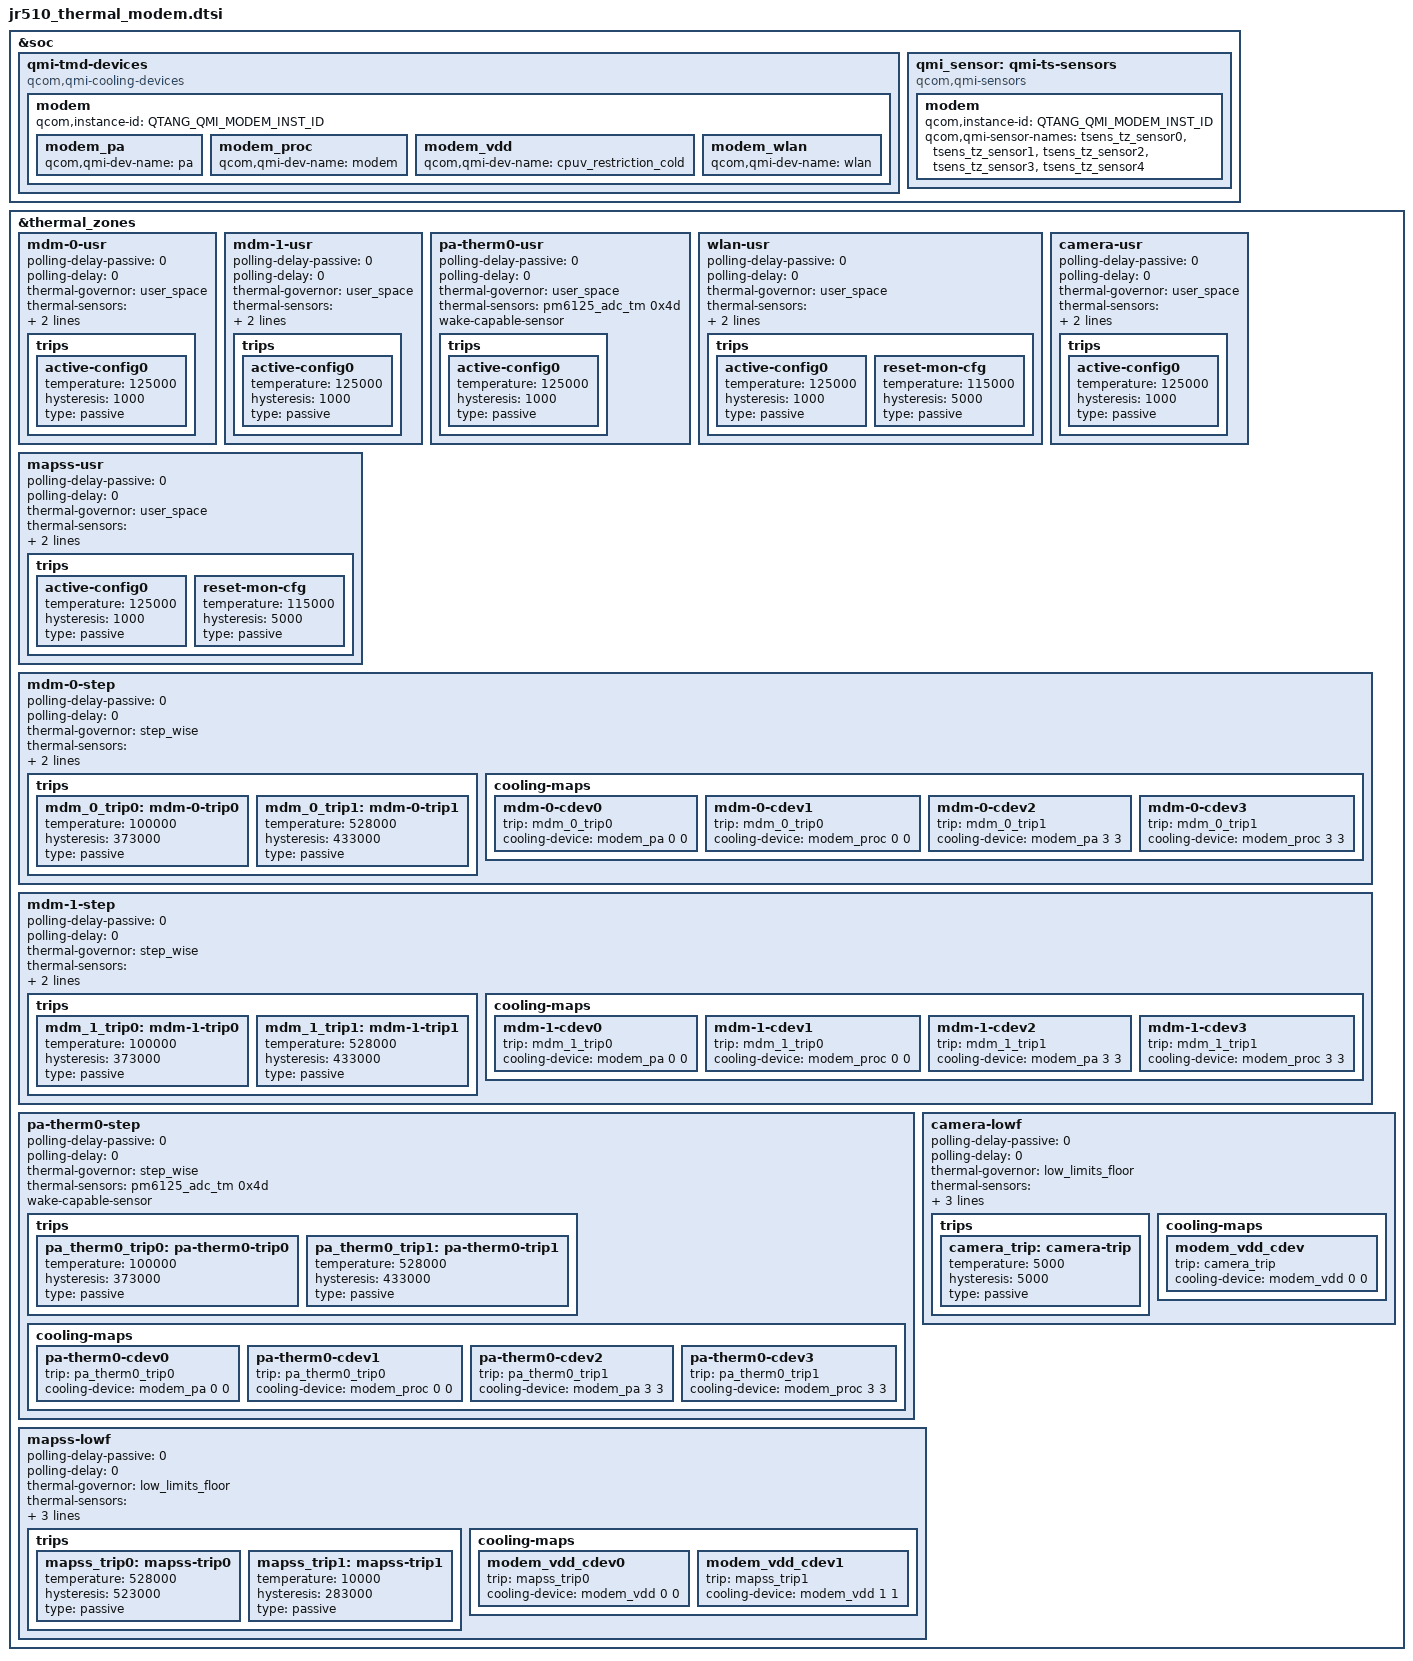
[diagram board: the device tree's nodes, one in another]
// SPDX-License-Identifier: GPL-2.0+

&soc {
	qmi-tmd-devices {
		compatible = "qcom,qmi-cooling-devices";

		modem {
			qcom,instance-id = <QTANG_QMI_MODEM_INST_ID>;

			modem_pa: modem_pa {
				qcom,qmi-dev-name = "pa";
				#cooling-cells = <2>;
			};

			modem_proc: modem_proc {
				qcom,qmi-dev-name = "modem";
				#cooling-cells = <2>;
			};

			modem_vdd: modem_vdd {
				qcom,qmi-dev-name = "cpuv_restriction_cold";
				#cooling-cells = <2>;
			};

			modem_wlan: modem_wlan {
				qcom,qmi-dev-name = "wlan";
				#cooling-cells = <2>;
			};

		};
	};

	qmi_sensor: qmi-ts-sensors {
		compatible = "qcom,qmi-sensors";
		#thermal-sensor-cells = <1>;

		modem {
			qcom,instance-id = <QTANG_QMI_MODEM_INST_ID>;
			qcom,qmi-sensor-names = "tsens_tz_sensor0",
						"tsens_tz_sensor1",
						"tsens_tz_sensor2",
						"tsens_tz_sensor3",
						"tsens_tz_sensor4";
		};
	};
};

&thermal_zones {

	mdm-0-usr {
		polling-delay-passive = <0>;
		polling-delay = <0>;
		thermal-governor = "user_space";
		thermal-sensors = <&qmi_sensor (QTANG_QMI_MODEM_INST_ID
					+QTANG_QMI_MODEM_TSENS_TZ_SENSOR4)>;
		wake-capable-sensor;
		trips {
			active-config0 {
				temperature = <125000>;
				hysteresis = <1000>;
				type = "passive";
			};
		};
	};

	mdm-1-usr {
		polling-delay-passive = <0>;
		polling-delay = <0>;
		thermal-governor = "user_space";
		thermal-sensors = <&qmi_sensor (QTANG_QMI_MODEM_INST_ID
					+QTANG_QMI_MODEM_TSENS_TZ_SENSOR3)>;
		wake-capable-sensor;
		trips {
			active-config0 {
				temperature = <125000>;
				hysteresis = <1000>;
				type = "passive";
			};
		};
	};

	pa-therm0-usr {
		polling-delay-passive = <0>;
		polling-delay = <0>;
		thermal-governor = "user_space";
		thermal-sensors = <&pm6125_adc_tm 0x4d>;
		wake-capable-sensor;
		trips {
			active-config0 {
				temperature = <125000>;
				hysteresis = <1000>;
				type = "passive";
			};
		};
	};

	wlan-usr {
		polling-delay-passive = <0>;
		polling-delay = <0>;
		thermal-governor = "user_space";
		thermal-sensors = <&qmi_sensor (QTANG_QMI_MODEM_INST_ID
					+QTANG_QMI_MODEM_TSENS_TZ_SENSOR1)>;
		wake-capable-sensor;
		trips {
			active-config0 {
				temperature = <125000>;
				hysteresis = <1000>;
				type = "passive";
			};

			reset-mon-cfg {
				temperature = <115000>;
				hysteresis = <5000>;
				type = "passive";
			};
		};
	};

	camera-usr {
		polling-delay-passive = <0>;
		polling-delay = <0>;
		thermal-governor = "user_space";
		thermal-sensors = <&qmi_sensor (QTANG_QMI_MODEM_INST_ID
					+QTANG_QMI_MODEM_TSENS_TZ_SENSOR2)>;
		wake-capable-sensor;
		trips {
			active-config0 {
				temperature = <125000>;
				hysteresis = <1000>;
				type = "passive";
			};
		};
	};

	mapss-usr {
		polling-delay-passive = <0>;
		polling-delay = <0>;
		thermal-governor = "user_space";
		thermal-sensors = <&qmi_sensor (QTANG_QMI_MODEM_INST_ID
					+QTANG_QMI_MODEM_TSENS_TZ_SENSOR0)>;
		wake-capable-sensor;
		trips {
			active-config0 {
				temperature = <125000>;
				hysteresis = <1000>;
				type = "passive";
			};

			reset-mon-cfg {
				temperature = <115000>;
				hysteresis = <5000>;
				type = "passive";
			};
		};
	};

	mdm-0-step {
		polling-delay-passive = <0>;
		polling-delay = <0>;
		thermal-governor = "step_wise";
		thermal-sensors = <&qmi_sensor (QTANG_QMI_MODEM_INST_ID
					+QTANG_QMI_MODEM_TSENS_TZ_SENSOR4)>;
		wake-capable-sensor;

		trips {

			mdm_0_trip0: mdm-0-trip0 {
				temperature = <100000>;
				hysteresis = <373000>;
				type = "passive";
			};

			mdm_0_trip1: mdm-0-trip1 {
				temperature = <528000>;
				hysteresis = <433000>;
				type = "passive";
			};

		};

		cooling-maps {
			mdm-0-cdev0 {
				trip = <&mdm_0_trip0>;
				cooling-device = <&modem_pa 0 0>;
			};
			mdm-0-cdev1 {
				trip = <&mdm_0_trip0>;
				cooling-device = <&modem_proc 0 0>;
			};
			mdm-0-cdev2 {
				trip = <&mdm_0_trip1>;
				cooling-device = <&modem_pa 3 3>;
			};
			mdm-0-cdev3 {
				trip = <&mdm_0_trip1>;
				cooling-device = <&modem_proc 3 3>;
			};
		};

	};

	mdm-1-step {
		polling-delay-passive = <0>;
		polling-delay = <0>;
		thermal-governor = "step_wise";
		thermal-sensors = <&qmi_sensor (QTANG_QMI_MODEM_INST_ID
					+QTANG_QMI_MODEM_TSENS_TZ_SENSOR3)>;
		wake-capable-sensor;

		trips {

			mdm_1_trip0: mdm-1-trip0 {
				temperature = <100000>;
				hysteresis = <373000>;
				type = "passive";
			};

			mdm_1_trip1: mdm-1-trip1 {
				temperature = <528000>;
				hysteresis = <433000>;
				type = "passive";
			};

		};

		cooling-maps {
			mdm-1-cdev0 {
				trip = <&mdm_1_trip0>;
				cooling-device = <&modem_pa 0 0>;
			};
			mdm-1-cdev1 {
				trip = <&mdm_1_trip0>;
				cooling-device = <&modem_proc 0 0>;
			};
			mdm-1-cdev2 {
				trip = <&mdm_1_trip1>;
				cooling-device = <&modem_pa 3 3>;
			};
			mdm-1-cdev3 {
				trip = <&mdm_1_trip1>;
				cooling-device = <&modem_proc 3 3>;
			};
		};
	};

	pa-therm0-step {
		polling-delay-passive = <0>;
		polling-delay = <0>;
		thermal-governor = "step_wise";
		thermal-sensors = <&pm6125_adc_tm 0x4d>;
		wake-capable-sensor;

		trips {

			pa_therm0_trip0: pa-therm0-trip0 {
				temperature = <100000>;
				hysteresis = <373000>;
				type = "passive";
			};

			pa_therm0_trip1: pa-therm0-trip1 {
				temperature = <528000>;
				hysteresis = <433000>;
				type = "passive";
			};

		};

		cooling-maps {
			pa-therm0-cdev0 {
				trip = <&pa_therm0_trip0>;
				cooling-device = <&modem_pa 0 0>;
			};
			pa-therm0-cdev1 {
				trip = <&pa_therm0_trip0>;
				cooling-device = <&modem_proc 0 0>;
			};
			pa-therm0-cdev2 {
				trip = <&pa_therm0_trip1>;
				cooling-device = <&modem_pa 3 3>;
			};
			pa-therm0-cdev3 {
				trip = <&pa_therm0_trip1>;
				cooling-device = <&modem_proc 3 3>;
			};
		};
	};

	camera-lowf {
		polling-delay-passive = <0>;
		polling-delay = <0>;
		thermal-governor = "low_limits_floor";
		thermal-sensors = <&qmi_sensor (QTANG_QMI_MODEM_INST_ID
					+QTANG_QMI_MODEM_TSENS_TZ_SENSOR2)>;
		wake-capable-sensor;
		tracks-low;

		trips {
			camera_trip: camera-trip {
				temperature = <5000>;
				hysteresis = <5000>;
				type = "passive";
			};
		};

		cooling-maps {
			//cx_vdd_cdev {
			//	trip = <&camera_trip>;
			//	cooling-device = <&cx_cdev 0 0>;
			//};

			modem_vdd_cdev {
				trip = <&camera_trip>;
				cooling-device = <&modem_vdd 0 0>;
			};
		};
	};

	mapss-lowf {
		polling-delay-passive = <0>;
		polling-delay = <0>;
		thermal-governor = "low_limits_floor";
		thermal-sensors = <&qmi_sensor (QTANG_QMI_MODEM_INST_ID
					+QTANG_QMI_MODEM_TSENS_TZ_SENSOR0)>;
		wake-capable-sensor;
		tracks-low;

		trips {
			mapss_trip0: mapss-trip0 {
				temperature = <528000>;
				hysteresis = <523000>;
				type = "passive";
			};

			mapss_trip1: mapss-trip1 {
				temperature = <10000>;
				hysteresis = <283000>;
				type = "passive";
			};
		};

		cooling-maps {

			modem_vdd_cdev0 {
				trip = <&mapss_trip0>;
				cooling-device = <&modem_vdd 0 0>;
			};

			modem_vdd_cdev1 {
				trip = <&mapss_trip1>;
				cooling-device = <&modem_vdd 1 1>;
			};
		};
	};

};
